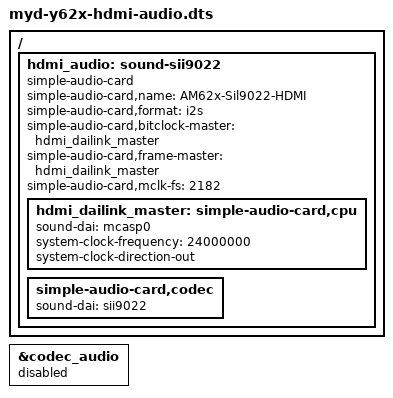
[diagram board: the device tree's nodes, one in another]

/dts-v1/;
/plugin/;

/ {
	fragment@101 {
		target-path = "/";

		__overlay__ {
			hdmi_audio: sound-sii9022 {
				compatible = "simple-audio-card";
				simple-audio-card,name = "AM62x-Sil9022-HDMI";
				simple-audio-card,format = "i2s";
				simple-audio-card,bitclock-master = <&hdmi_dailink_master>;
				simple-audio-card,frame-master = <&hdmi_dailink_master>;
				simple-audio-card,mclk-fs = <2182>;

				hdmi_dailink_master: simple-audio-card,cpu {
					sound-dai = <&mcasp0>;
					system-clock-frequency = <24000000>;
					system-clock-direction-out;
				};

				simple-audio-card,codec {
					sound-dai = <&sii9022>;
				};
			};
		};
	};
};

&codec_audio {
	status = "disabled";
};
